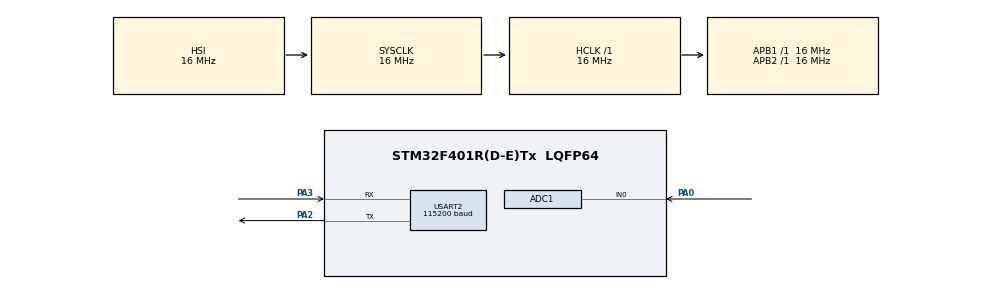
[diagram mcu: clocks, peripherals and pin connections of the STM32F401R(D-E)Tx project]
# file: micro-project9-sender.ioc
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ADC1.Channel-0\#ChannelRegularConversion=ADC_CHANNEL_0
ADC1.ExternalTrigConv=ADC_EXTERNALTRIGCONV_T2_TRGO
ADC1.NbrOfConversionFlag=1
ADC1.Rank-0\#ChannelRegularConversion=1
ADC1.SamplingTime-0\#ChannelRegularConversion=ADC_SAMPLETIME_3CYCLES
ADC1.master=1
Mcu.Family=STM32F4
Mcu.Name=STM32F401R(D-E)Tx
Mcu.Package=LQFP64
NVIC.ADC_IRQn=true\:0\:0\:false\:false\:true\:true\:true
NVIC.PriorityGroup=NVIC_PRIORITYGROUP_4
PA0-WKUP.Signal=ADCx_IN0
PA2.Mode=Asynchronous
PA2.Signal=USART2_TX
PA3.Mode=Asynchronous
PA3.Signal=USART2_RX
ProjectManager.HeapSize=0x200
ProjectManager.StackSize=0x400
ProjectManager.TargetToolchain=MDK-ARM V5
RCC.AHBFreq_Value=16000000
RCC.APB1Freq_Value=16000000
RCC.APB2Freq_Value=16000000
RCC.CortexFreq_Value=16000000
RCC.HSE_VALUE=25000000
RCC.HSI_VALUE=16000000
RCC.LSE_VALUE=32768
RCC.SYSCLKFreq_VALUE=16000000
RCC.VCOOutputFreq_Value=192000000
SH.ADCx_IN0.0=ADC1_IN0,IN0
TIM2.Channel-Output\ Compare2\ No\ Output=TIM_CHANNEL_2
TIM2.Period=999
TIM2.Prescaler=15999
TIM2.TIM_MasterOutputTrigger=TIM_TRGO_UPDATE
USART2.BaudRate=115200
USART2.Mode=MODE_TX
USART2.VirtualMode=VM_ASYNC
VP_TIM2_VS_ClockSourceINT.Mode=Internal
VP_TIM2_VS_no_output2.Mode=Output Compare2 No Output
board=custom

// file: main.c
/* USER CODE BEGIN Header */
/**
  ******************************************************************************
  * @file           : main.c
  * @brief          : Main program body
  ******************************************************************************
  * @attention
  *
  * Copyright (c) 2022 STMicroelectronics.
  * All rights reserved.
  *
  * This software is licensed under terms that can be found in the LICENSE file
  * in the root directory of this software component.
  * If no LICENSE file comes with this software, it is provided AS-IS.
  *
  ******************************************************************************
  */
/* USER CODE END Header */
#include "main.h"
#include "adc.h"
#include "tim.h"
#include "usart.h"
#include "gpio.h"

/* USER CODE BEGIN Includes */
#include <string.h>
#include <stdio.h>
/* USER CODE END Includes */

void SystemClock_Config(void);

/* USER CODE BEGIN 0 */
void sendString(char* string){
	HAL_UART_Transmit(&huart2,(uint8_t*) string , strlen(string), HAL_MAX_DELAY);
}
void newLine(){
	sendString("\n\r");
}

void HAL_ADC_ConvCpltCallback(ADC_HandleTypeDef* hadc){
	uint32_t adc_value = HAL_ADC_GetValue(&hadc1);
	double res = ((double) adc_value );
	res /= 4095.0;
	res *= 3.3;
	res *= 10;
	adc_value = res;
	char buff[2];
	sprintf(buff, "%u", adc_value);
	sendString(buff);
}
/* USER CODE END 0 */

int main(void)
{

  /* MCU Configuration--------------------------------------------------------*/

  /* Reset of all peripherals, Initializes the Flash interface and the Systick. */
  HAL_Init();

  /* Configure the system clock */
  SystemClock_Config();

  /* Initialize all configured peripherals */
  MX_GPIO_Init();
  MX_ADC1_Init();
  MX_TIM2_Init();
  MX_USART2_UART_Init();
  /* USER CODE BEGIN 2 */
	HAL_TIM_Base_Start(&htim2);
	HAL_ADC_Start_IT(&hadc1);
  /* USER CODE END 2 */

  /* Infinite loop */
  while (1)
  {

  }
}

void SystemClock_Config(void)
{
  RCC_OscInitTypeDef RCC_OscInitStruct = {0};
  RCC_ClkInitTypeDef RCC_ClkInitStruct = {0};

  /** Configure the main internal regulator output voltage
  */
  __HAL_RCC_PWR_CLK_ENABLE();
  __HAL_PWR_VOLTAGESCALING_CONFIG(PWR_REGULATOR_VOLTAGE_SCALE2);
  /** Initializes the RCC Oscillators according to the specified parameters
  * in the RCC_OscInitTypeDef structure.
  */
  RCC_OscInitStruct.OscillatorType = RCC_OSCILLATORTYPE_HSI;
  RCC_OscInitStruct.HSIState = RCC_HSI_ON;
  RCC_OscInitStruct.HSICalibrationValue = RCC_HSICALIBRATION_DEFAULT;
  RCC_OscInitStruct.PLL.PLLState = RCC_PLL_NONE;
  if (HAL_RCC_OscConfig(&RCC_OscInitStruct) != HAL_OK)
  {
    Error_Handler();
  }
  /** Initializes the CPU, AHB and APB buses clocks
  */
  RCC_ClkInitStruct.ClockType = RCC_CLOCKTYPE_HCLK|RCC_CLOCKTYPE_SYSCLK
                              |RCC_CLOCKTYPE_PCLK1|RCC_CLOCKTYPE_PCLK2;
  RCC_ClkInitStruct.SYSCLKSource = RCC_SYSCLKSOURCE_HSI;
  RCC_ClkInitStruct.AHBCLKDivider = RCC_SYSCLK_DIV1;
  RCC_ClkInitStruct.APB1CLKDivider = RCC_HCLK_DIV1;
  RCC_ClkInitStruct.APB2CLKDivider = RCC_HCLK_DIV1;

  if (HAL_RCC_ClockConfig(&RCC_ClkInitStruct, FLASH_LATENCY_0) != HAL_OK)
  {
    Error_Handler();
  }
}

void Error_Handler(void)
{
  __disable_irq();
  while (1)
  {
  }
}
